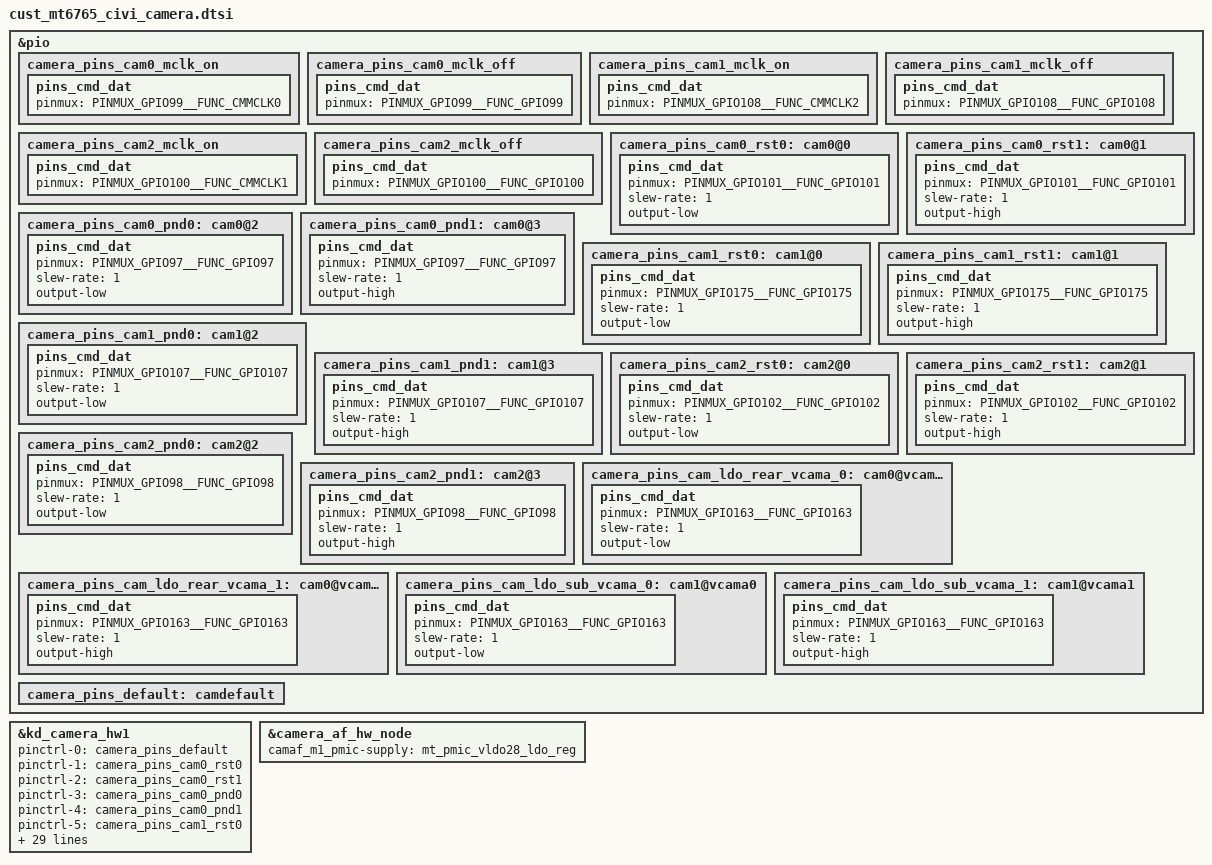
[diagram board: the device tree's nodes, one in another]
// SPDX-License-Identifier: GPL-2.0+

/* CAMERA GPIO standardization */

//Begin modified by liangjiaqiang for civic camera on 2022.7.6
&pio {
	camera_pins_cam0_mclk_on: camera_pins_cam0_mclk_on {
		pins_cmd_dat {
			pinmux = <PINMUX_GPIO99__FUNC_CMMCLK0>;
		};
	};
	camera_pins_cam0_mclk_off: camera_pins_cam0_mclk_off {
		pins_cmd_dat {
			pinmux = <PINMUX_GPIO99__FUNC_GPIO99>;
		};
	};
	camera_pins_cam1_mclk_on: camera_pins_cam1_mclk_on {
		pins_cmd_dat {
			pinmux = <PINMUX_GPIO108__FUNC_CMMCLK2>;
		};
	};
	camera_pins_cam1_mclk_off: camera_pins_cam1_mclk_off {
		pins_cmd_dat {
			pinmux = <PINMUX_GPIO108__FUNC_GPIO108>;
		};
	};
	camera_pins_cam2_mclk_on: camera_pins_cam2_mclk_on {
		pins_cmd_dat {
			pinmux = <PINMUX_GPIO100__FUNC_CMMCLK1>;
		};
	};
	camera_pins_cam2_mclk_off: camera_pins_cam2_mclk_off {
		pins_cmd_dat {
			pinmux = <PINMUX_GPIO100__FUNC_GPIO100>;
		};
	};
	camera_pins_cam0_rst0: cam0@0 {
		pins_cmd_dat {
			pinmux = <PINMUX_GPIO101__FUNC_GPIO101>;
			slew-rate = <1>;
			output-low;
		};
	};
	camera_pins_cam0_rst1: cam0@1 {
		pins_cmd_dat {
			pinmux = <PINMUX_GPIO101__FUNC_GPIO101>;
			slew-rate = <1>;
			output-high;
		};
	};
	camera_pins_cam0_pnd0: cam0@2 {
		pins_cmd_dat {
			pinmux = <PINMUX_GPIO97__FUNC_GPIO97>;
			slew-rate = <1>;
			output-low;
		};
	};
	camera_pins_cam0_pnd1: cam0@3 {
		pins_cmd_dat {
			pinmux = <PINMUX_GPIO97__FUNC_GPIO97>;
			slew-rate = <1>;
			output-high;
		};
	};
	camera_pins_cam1_rst0: cam1@0 {
		pins_cmd_dat {
			pinmux = <PINMUX_GPIO175__FUNC_GPIO175>;
			slew-rate = <1>;
			output-low;
		};
	};
	camera_pins_cam1_rst1: cam1@1 {
		pins_cmd_dat {
			pinmux = <PINMUX_GPIO175__FUNC_GPIO175>;
			slew-rate = <1>;
			output-high;
		};
	};
	camera_pins_cam1_pnd0: cam1@2 {
		pins_cmd_dat {
			pinmux = <PINMUX_GPIO107__FUNC_GPIO107>;
			slew-rate = <1>;
			output-low;
		};
	};
	camera_pins_cam1_pnd1: cam1@3 {
		pins_cmd_dat {
			pinmux = <PINMUX_GPIO107__FUNC_GPIO107>;
			slew-rate = <1>;
			output-high;
		};
	};
	camera_pins_cam2_rst0: cam2@0 {
		pins_cmd_dat {
			pinmux = <PINMUX_GPIO102__FUNC_GPIO102>;
			slew-rate = <1>;
			output-low;
		};
	};
	camera_pins_cam2_rst1: cam2@1 {
		pins_cmd_dat {
			pinmux = <PINMUX_GPIO102__FUNC_GPIO102>;
			slew-rate = <1>;
			output-high;
		};
	};
	camera_pins_cam2_pnd0: cam2@2 {
		pins_cmd_dat {
			pinmux = <PINMUX_GPIO98__FUNC_GPIO98>;
			slew-rate = <1>;
			output-low;
		};
	};
	camera_pins_cam2_pnd1: cam2@3 {
		pins_cmd_dat {
			pinmux = <PINMUX_GPIO98__FUNC_GPIO98>;
			slew-rate = <1>;
			output-high;
		};
	};
//Begin added by liangjiaqiang for CIVIC-3638 on 2022-08-17
	camera_pins_cam_ldo_rear_vcama_0: cam0@vcama0 {
		pins_cmd_dat {
			pinmux = <PINMUX_GPIO163__FUNC_GPIO163>;
			slew-rate = <1>;
			output-low;
		};
	};
	camera_pins_cam_ldo_rear_vcama_1: cam0@vcama1 {
		pins_cmd_dat {
			pinmux = <PINMUX_GPIO163__FUNC_GPIO163>;
			slew-rate = <1>;
			output-high;
		};
	};
	camera_pins_cam_ldo_sub_vcama_0: cam1@vcama0 {
		pins_cmd_dat {
			pinmux = <PINMUX_GPIO163__FUNC_GPIO163>;
			slew-rate = <1>;
			output-low;
		};
	};
	camera_pins_cam_ldo_sub_vcama_1: cam1@vcama1 {
		pins_cmd_dat {
			pinmux = <PINMUX_GPIO163__FUNC_GPIO163>;
			slew-rate = <1>;
			output-high;
		};
	};
//End added by liangjiaqiang for CIVIC-3638 on 2022-08-17
	camera_pins_default: camdefault {
	};

};

&kd_camera_hw1 {
	pinctrl-names = "default",
			"cam0_rst0",
			"cam0_rst1",
			"cam0_pnd0",
			"cam0_pnd1",
			"cam1_rst0",
			"cam1_rst1",
			"cam1_pnd0",
			"cam1_pnd1",
			"cam2_rst0",
			"cam2_rst1",
			"cam2_pnd0",
			"cam2_pnd1",
//Begin added by liangjiaqiang for CIVIC-3638 on 2022-08-17
			"cam0_vcama_on",
			"cam0_vcama_off",
			"cam1_vcama_on",
			"cam1_vcama_off",
//End added by liangjiaqiang for CIVIC-3638 on 2022-08-17
			"cam0_mclk_on",
			"cam0_mclk_off",
			"cam1_mclk_on",
			"cam1_mclk_off",
			"cam2_mclk_on",
			"cam2_mclk_off";

	pinctrl-0 = <&camera_pins_default>;
	pinctrl-1 = <&camera_pins_cam0_rst0>;
	pinctrl-2 = <&camera_pins_cam0_rst1>;
	pinctrl-3 = <&camera_pins_cam0_pnd0>;
	pinctrl-4 = <&camera_pins_cam0_pnd1>;
	pinctrl-5 = <&camera_pins_cam1_rst0>;
	pinctrl-6 = <&camera_pins_cam1_rst1>;
	pinctrl-7 = <&camera_pins_cam1_pnd0>;
	pinctrl-8 = <&camera_pins_cam1_pnd1>;
	pinctrl-9 = <&camera_pins_cam2_rst0>;
	pinctrl-10 = <&camera_pins_cam2_rst1>;
	pinctrl-11 = <&camera_pins_cam2_pnd0>;
	pinctrl-12 = <&camera_pins_cam2_pnd1>;
//Begin added by liangjiaqiang for CIVIC-3638 on 2022-08-17
	pinctrl-13 = <&camera_pins_cam_ldo_rear_vcama_1>;
	pinctrl-14 = <&camera_pins_cam_ldo_rear_vcama_0>;
	pinctrl-15 = <&camera_pins_cam_ldo_sub_vcama_1>;
	pinctrl-16 = <&camera_pins_cam_ldo_sub_vcama_0>;
//End added by liangjiaqiang for CIVIC-3638 on 2022-08-17
	pinctrl-17 = <&camera_pins_cam0_mclk_on>;
	pinctrl-18 = <&camera_pins_cam0_mclk_off>;
	pinctrl-19 = <&camera_pins_cam1_mclk_on>;
	pinctrl-20 = <&camera_pins_cam1_mclk_off>;
	pinctrl-21 = <&camera_pins_cam2_mclk_on>;
	pinctrl-22 = <&camera_pins_cam2_mclk_off>;

	cam2_vcama-supply = <&mt_pmic_vcama_ldo_reg>;
	
	cam0_vcamd-supply = <&mt_pmic_vcamd_ldo_reg>;
	cam1_vcamd-supply = <&mt_pmic_vcamd_ldo_reg>;
	cam2_vcamd-supply = <&mt_pmic_vcamd_ldo_reg>;
	
	cam0_vcamio-supply = <&mt_pmic_vcamio_ldo_reg>;
	cam1_vcamio-supply = <&mt_pmic_vcamio_ldo_reg>;
	cam2_vcamio-supply = <&mt_pmic_vcamio_ldo_reg>;
	
	cam0_enable_sensor = "gdir220061_hi1336_mipi_raw swlu7166_gc13a0_mipi_raw";
	cam1_enable_sensor = "ctxvm15797_gc5035_mipi_raw lhvm15798_gc05a2_mipi_raw";
	cam2_enable_sensor = "ctxvc12800_gc02m1_mipi_raw";
	status = "okay";

};

&camera_af_hw_node {
	camaf_m1_pmic-supply = <&mt_pmic_vldo28_ldo_reg>;
	status = "okay";
};
//End modified by liangjiaqiang for civic camera on 2022.7.6

/* CAMERA GPIO end */
